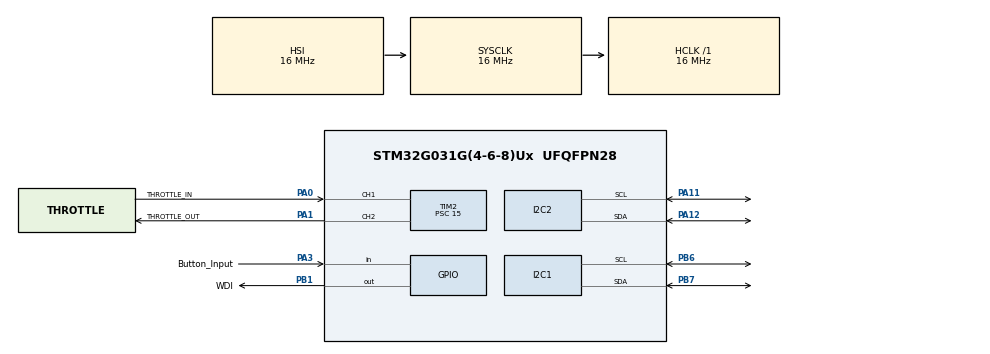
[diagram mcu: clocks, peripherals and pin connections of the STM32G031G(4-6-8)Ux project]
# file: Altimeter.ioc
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Mcu.Family=STM32G0
Mcu.Name=STM32G031G(4-6-8)Ux
Mcu.Package=UFQFPN28
NVIC.TIM2_IRQn=true\:0\:0\:false\:false\:true\:false\:true\:false
PA0.GPIO_Label=THROTTLE_IN
PA0.Signal=S_TIM2_CH1_ETR
PA1.GPIO_Label=THROTTLE_OUT
PA1.Signal=S_TIM2_CH2
PA11\ [PA9].Mode=I2C
PA11\ [PA9].Signal=I2C2_SCL
PA12\ [PA10].Mode=I2C
PA12\ [PA10].Signal=I2C2_SDA
PA13.Mode=Serial_Wire
PA13.Signal=SYS_SWDIO
PA14-BOOT0.Mode=Serial_Wire
PA14-BOOT0.Signal=SYS_SWCLK
PA3.GPIO_Label=Button_Input
PA3.Signal=GPIO_Input
PB1.GPIO_Label=WDI
PB1.Signal=GPIO_Output
PB6.Mode=I2C
PB6.Signal=I2C1_SCL
PB7.Mode=I2C
PB7.Signal=I2C1_SDA
ProjectManager.HeapSize=0x200
ProjectManager.StackSize=0x400
ProjectManager.TargetToolchain=MDK-ARM V5.32
RCC.AHBFreq_Value=16000000
RCC.CortexFreq_Value=16000000
RCC.EXTERNAL_CLOCK_VALUE=12288000
RCC.HCLKFreq_Value=16000000
RCC.HSE_VALUE=8000000
RCC.HSI_VALUE=16000000
RCC.LSE_VALUE=32768
RCC.SYSCLKFreq_VALUE=16000000
RCC.VCOOutputFreq_Value=128000000
SH.S_TIM2_CH1_ETR.0=TIM2_CH1,Input_Capture1_from_TI1
SH.S_TIM2_CH2.0=TIM2_CH2,PWM Generation2 CH2
TIM2.AutoReloadPreload=TIM_AUTORELOAD_PRELOAD_ENABLE
TIM2.Channel-Input_Capture1_from_TI1=TIM_CHANNEL_1
TIM2.Channel-PWM\ Generation2\ CH2=TIM_CHANNEL_2
TIM2.ICFilter_CH1=4
TIM2.ICPolarity_CH1=TIM_INPUTCHANNELPOLARITY_BOTHEDGE
TIM2.Period=20000
TIM2.Prescaler=15
TIM2.Pulse-PWM\ Generation2\ CH2=100
board=custom

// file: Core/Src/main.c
/* USER CODE BEGIN Header */
/**
  ******************************************************************************
  * @file           : main.c
  * @brief          : Main program body
  ******************************************************************************
  * @attention
  *
  * Copyright (c) 2026 STMicroelectronics.
  * All rights reserved.
  *
  * This software is licensed under terms that can be found in the LICENSE file
  * in the root directory of this software component.
  * If no LICENSE file comes with this software, it is provided AS-IS.
  *
  ******************************************************************************
  */
/* USER CODE END Header */
#include "main.h"

/* USER CODE BEGIN Includes */
#include "throttle.h"
#include "watchdog_kick.h"
#include "button.h"
#include "altimeter_fsm.h"
/* USER CODE END Includes */

I2C_HandleTypeDef hi2c1;
I2C_HandleTypeDef hi2c2;

TIM_HandleTypeDef htim2;

void SystemClock_Config(void);
static void MX_GPIO_Init(void);
static void MX_I2C1_Init(void);
static void MX_I2C2_Init(void);
static void MX_TIM2_Init(void);

int main(void)
{

  /* MCU Configuration--------------------------------------------------------*/

  /* Reset of all peripherals, Initializes the Flash interface and the Systick. */
  HAL_Init();

  /* Configure the system clock */
  SystemClock_Config();

  /* Initialize all configured peripherals */
  MX_GPIO_Init();
  MX_I2C1_Init();
  MX_I2C2_Init();
  MX_TIM2_Init();
  /* USER CODE BEGIN 2 */

  /* Bring-up order matters: WDI first (so we can start servicing the
   * external supervisor immediately), then the throttle output (forces
   * safe idle before PWM is enabled), then the FSM (sensor/display init +
   * enters ZEROING). Button needs no explicit init beyond MX_GPIO_Init(). */
  WDI_Init();
  Throttle_Init();
  FSM_Init();

  /* USER CODE END 2 */

  /* Infinite loop */
  while (1)
  {

    /* USER CODE BEGIN 3 */
    Throttle_Process();
    Button_Process();
    FSM_Tick();

    /* Kick the external watchdog last, from the completed main loop only
     * (never from an isolated ISR) -- see watchdog_kick.h. */
    WDI_Kick();
  }
  /* USER CODE END 3 */
}

void SystemClock_Config(void)
{
  RCC_OscInitTypeDef RCC_OscInitStruct = {0};
  RCC_ClkInitTypeDef RCC_ClkInitStruct = {0};

  /** Configure the main internal regulator output voltage
  */
  HAL_PWREx_ControlVoltageScaling(PWR_REGULATOR_VOLTAGE_SCALE1);

  /** Initializes the RCC Oscillators according to the specified parameters
  * in the RCC_OscInitTypeDef structure.
  */
  RCC_OscInitStruct.OscillatorType = RCC_OSCILLATORTYPE_HSI;
  RCC_OscInitStruct.HSIState = RCC_HSI_ON;
  RCC_OscInitStruct.HSIDiv = RCC_HSI_DIV1;
  RCC_OscInitStruct.HSICalibrationValue = RCC_HSICALIBRATION_DEFAULT;
  RCC_OscInitStruct.PLL.PLLState = RCC_PLL_NONE;
  if (HAL_RCC_OscConfig(&RCC_OscInitStruct) != HAL_OK)
  {
    Error_Handler();
  }

  /** Initializes the CPU, AHB and APB buses clocks
  */
  RCC_ClkInitStruct.ClockType = RCC_CLOCKTYPE_HCLK|RCC_CLOCKTYPE_SYSCLK
                              |RCC_CLOCKTYPE_PCLK1;
  RCC_ClkInitStruct.SYSCLKSource = RCC_SYSCLKSOURCE_HSI;
  RCC_ClkInitStruct.AHBCLKDivider = RCC_SYSCLK_DIV1;
  RCC_ClkInitStruct.APB1CLKDivider = RCC_HCLK_DIV1;

  if (HAL_RCC_ClockConfig(&RCC_ClkInitStruct, FLASH_LATENCY_0) != HAL_OK)
  {
    Error_Handler();
  }
}

static void MX_I2C1_Init(void)
{

  hi2c1.Instance = I2C1;
  hi2c1.Init.Timing = 0x00303D5B;
  hi2c1.Init.OwnAddress1 = 0;
  hi2c1.Init.AddressingMode = I2C_ADDRESSINGMODE_7BIT;
  hi2c1.Init.DualAddressMode = I2C_DUALADDRESS_DISABLE;
  hi2c1.Init.OwnAddress2 = 0;
  hi2c1.Init.OwnAddress2Masks = I2C_OA2_NOMASK;
  hi2c1.Init.GeneralCallMode = I2C_GENERALCALL_DISABLE;
  hi2c1.Init.NoStretchMode = I2C_NOSTRETCH_DISABLE;
  if (HAL_I2C_Init(&hi2c1) != HAL_OK)
  {
    Error_Handler();
  }

  /** Configure Analogue filter
  */
  if (HAL_I2CEx_ConfigAnalogFilter(&hi2c1, I2C_ANALOGFILTER_ENABLE) != HAL_OK)
  {
    Error_Handler();
  }

  /** Configure Digital filter
  */
  if (HAL_I2CEx_ConfigDigitalFilter(&hi2c1, 0) != HAL_OK)
  {
    Error_Handler();
  }

}

static void MX_I2C2_Init(void)
{

  hi2c2.Instance = I2C2;
  hi2c2.Init.Timing = 0x00303D5B;
  hi2c2.Init.OwnAddress1 = 0;
  hi2c2.Init.AddressingMode = I2C_ADDRESSINGMODE_7BIT;
  hi2c2.Init.DualAddressMode = I2C_DUALADDRESS_DISABLE;
  hi2c2.Init.OwnAddress2 = 0;
  hi2c2.Init.OwnAddress2Masks = I2C_OA2_NOMASK;
  hi2c2.Init.GeneralCallMode = I2C_GENERALCALL_DISABLE;
  hi2c2.Init.NoStretchMode = I2C_NOSTRETCH_DISABLE;
  if (HAL_I2C_Init(&hi2c2) != HAL_OK)
  {
    Error_Handler();
  }

  /** Configure Analogue filter
  */
  if (HAL_I2CEx_ConfigAnalogFilter(&hi2c2, I2C_ANALOGFILTER_ENABLE) != HAL_OK)
  {
    Error_Handler();
  }

  /** Configure Digital filter
  */
  if (HAL_I2CEx_ConfigDigitalFilter(&hi2c2, 0) != HAL_OK)
  {
    Error_Handler();
  }

}

static void MX_TIM2_Init(void)
{

  TIM_MasterConfigTypeDef sMasterConfig = {0};
  TIM_IC_InitTypeDef sConfigIC = {0};
  TIM_OC_InitTypeDef sConfigOC = {0};

  htim2.Instance = TIM2;
  htim2.Init.Prescaler = 15;
  htim2.Init.CounterMode = TIM_COUNTERMODE_UP;
  htim2.Init.Period = 20000;
  htim2.Init.ClockDivision = TIM_CLOCKDIVISION_DIV1;
  htim2.Init.AutoReloadPreload = TIM_AUTORELOAD_PRELOAD_ENABLE;
  if (HAL_TIM_IC_Init(&htim2) != HAL_OK)
  {
    Error_Handler();
  }
  if (HAL_TIM_PWM_Init(&htim2) != HAL_OK)
  {
    Error_Handler();
  }
  sMasterConfig.MasterOutputTrigger = TIM_TRGO_RESET;
  sMasterConfig.MasterSlaveMode = TIM_MASTERSLAVEMODE_DISABLE;
  if (HAL_TIMEx_MasterConfigSynchronization(&htim2, &sMasterConfig) != HAL_OK)
  {
    Error_Handler();
  }
  sConfigIC.ICPolarity = TIM_INPUTCHANNELPOLARITY_BOTHEDGE;
  sConfigIC.ICSelection = TIM_ICSELECTION_DIRECTTI;
  sConfigIC.ICPrescaler = TIM_ICPSC_DIV1;
  sConfigIC.ICFilter = 4;
  if (HAL_TIM_IC_ConfigChannel(&htim2, &sConfigIC, TIM_CHANNEL_1) != HAL_OK)
  {
    Error_Handler();
  }
  sConfigOC.OCMode = TIM_OCMODE_PWM1;
  sConfigOC.Pulse = 100;
  sConfigOC.OCPolarity = TIM_OCPOLARITY_HIGH;
  sConfigOC.OCFastMode = TIM_OCFAST_DISABLE;
  if (HAL_TIM_PWM_ConfigChannel(&htim2, &sConfigOC, TIM_CHANNEL_2) != HAL_OK)
  {
    Error_Handler();
  }
  HAL_TIM_MspPostInit(&htim2);

}

static void MX_GPIO_Init(void)
{
  GPIO_InitTypeDef GPIO_InitStruct = {0};

  /* GPIO Ports Clock Enable */
  __HAL_RCC_GPIOA_CLK_ENABLE();
  __HAL_RCC_GPIOB_CLK_ENABLE();

  /*Configure GPIO pin Output Level */
  HAL_GPIO_WritePin(WDI_GPIO_Port, WDI_Pin, GPIO_PIN_RESET);

  /*Configure GPIO pin : Button_Input_Pin */
  GPIO_InitStruct.Pin = Button_Input_Pin;
  GPIO_InitStruct.Mode = GPIO_MODE_INPUT;
  GPIO_InitStruct.Pull = GPIO_NOPULL;
  HAL_GPIO_Init(Button_Input_GPIO_Port, &GPIO_InitStruct);

  /*Configure GPIO pin : WDI_Pin */
  GPIO_InitStruct.Pin = WDI_Pin;
  GPIO_InitStruct.Mode = GPIO_MODE_OUTPUT_PP;
  GPIO_InitStruct.Pull = GPIO_NOPULL;
  GPIO_InitStruct.Speed = GPIO_SPEED_FREQ_LOW;
  HAL_GPIO_Init(WDI_GPIO_Port, &GPIO_InitStruct);

}

void Error_Handler(void)
{
  __disable_irq();
  while (1)
  {
  }
}
